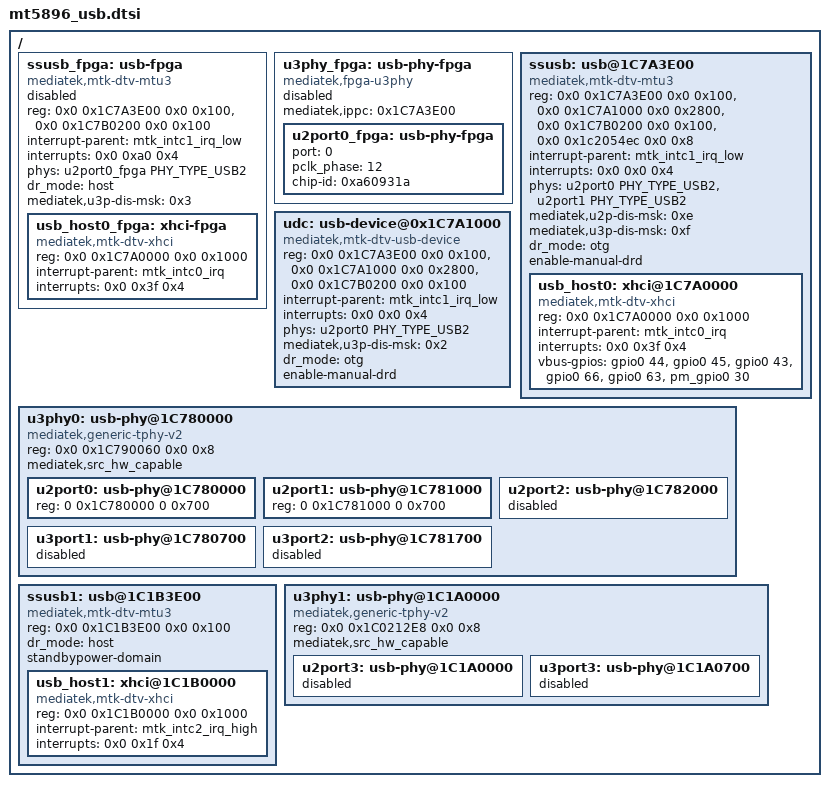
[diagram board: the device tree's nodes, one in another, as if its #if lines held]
// SPDX-License-Identifier: (GPL-2.0 OR BSD-3-Clause)
/*
 * Copyright (c) 2020 MediaTek Inc.
 */

/ {
	ssusb_fpga: usb-fpga {
		compatible = "mediatek,mtk-dtv-mtu3";
		reg = <0x0 0x1C7A3E00 0x0 0x100>,
			<0x0 0x1C7B0200 0x0 0x100>;
		reg-names = "ippc", "misc";
		interrupt-parent = <&mtk_intc1_irq_low>;
		interrupts = <0x0 0xa0 0x4>;
		phys = <&u2port0_fpga PHY_TYPE_USB2>;
		dr_mode = "host";
		#address-cells = <2>;
		#size-cells = <2>;
		ranges;
		mediatek,u3p-dis-msk = <0x3>;
		status = "disabled";

		usb_host0_fpga: xhci-fpga {
			compatible = "mediatek,mtk-dtv-xhci";
			reg = <0x0 0x1C7A0000 0x0 0x1000>;
			reg-names = "mac";
			interrupt-parent = <&mtk_intc0_irq>;
			interrupts = <0x0 0x3f 0x4>;
		};
	};

	u3phy_fpga: usb-phy-fpga {
		compatible = "mediatek,fpga-u3phy";
		mediatek,ippc = <0x1C7A3E00>;
		status = "disabled";

		u2port0_fpga: usb-phy-fpga {
			port = <0>;
			pclk_phase = <12>;
			chip-id = <0xa60931a>;
			#phy-cells = <1>;
		};
	};

	ssusb: usb@1C7A3E00 {
		compatible = "mediatek,mtk-dtv-mtu3";
		reg = <0x0 0x1C7A3E00 0x0 0x100>,
			<0x0 0x1C7A1000 0x0 0x2800>,
			<0x0 0x1C7B0200 0x0 0x100>,
			<0x0 0x1c2054ec 0x0 0x8>;
		reg-names = "ippc","mac","misc","dma_gt";
		interrupt-parent = <&mtk_intc1_irq_low>;
		interrupts = <0x0 0x0 0x4>;
		phys = <&u2port0 PHY_TYPE_USB2>,
			<&u2port1 PHY_TYPE_USB2>/*,
			<&u2port2 PHY_TYPE_USB2>,
			<&u3port1 PHY_TYPE_USB3>,
			<&u3port2 PHY_TYPE_USB3>*/;
#ifdef CONFIG_USB_XHCI_MTK_BOOT_PORT
		mediatek,u2p-dis-msk = <0xe>;
		mediatek,u3p-dis-msk = <0xf>;
#else
		mediatek,u3p-dis-msk = <0x2>;
#endif
		dr_mode = "otg";
		enable-manual-drd;
		#address-cells = <2>;
		#size-cells = <2>;
		ranges;
		status ="okay";

		usb_host0: xhci@1C7A0000 {
			compatible = "mediatek,mtk-dtv-xhci";
			reg = <0x0 0x1C7A0000 0x0 0x1000>;
			reg-names = "mac";
			interrupt-parent = <&mtk_intc0_irq>;
			interrupts = <0x0 0x3f 0x4>;
			vbus-gpios = <&gpio0 44 0>,
					<&gpio0 45 0>,
					<&gpio0 43 0>,
					<&gpio0 66 0>,
					<&gpio0 63 0>,
					<&pm_gpio0 30 0>;
			status ="okay";
		};
	};
	udc: usb-device@0x1C7A1000 {
		compatible = "mediatek,mtk-dtv-usb-device";
		reg = <0x0 0x1C7A3E00 0x0 0x100>,
			<0x0 0x1C7A1000 0x0 0x2800>,
			<0x0 0x1C7B0200 0x0 0x100>;
		reg-names = "ippc","mac","misc";
		interrupt-parent = <&mtk_intc1_irq_low>;
		interrupts = <0x0 0x0 0x4>;
		phys = <&u2port0 PHY_TYPE_USB2>;
		mediatek,u3p-dis-msk = <0x2>;
		dr_mode = "otg";
		enable-manual-drd;
		#address-cells = <2>;
		#size-cells = <2>;
		ranges;
		status ="okay";
		};
	u3phy0: usb-phy@1C780000 {
		compatible = "mediatek,generic-tphy-v2";
		reg = <0x0 0x1C790060 0x0 0x8>;
		reg-names = "i2c_ctrl_reg";
		#address-cells = <2>;
		#size-cells = <2>;
		mediatek,src_hw_capable;
		ranges;
		status = "okay";

		u2port0: usb-phy@1C780000 {
			reg = <0 0x1C780000 0 0x700>;
			#phy-cells = <1>;
			status = "okay";
		};

		u2port1: usb-phy@1C781000 {
			reg = <0 0x1C781000 0 0x700>;
			#phy-cells = <1>;
			status = "okay";
		};

		u2port2: usb-phy@1C782000 {
			status = "disabled";
		};

		u3port1: usb-phy@1C780700 {
			status = "disabled";
		};

		u3port2: usb-phy@1C781700 {
			status = "disabled";
		};
	};

	ssusb1: usb@1C1B3E00 {
		compatible = "mediatek,mtk-dtv-mtu3";
		reg = <0x0 0x1C1B3E00 0x0 0x100>;
		reg-names = "ippc";
		dr_mode = "host";
		#address-cells = <2>;
		#size-cells = <2>;
		ranges;
		standbypower-domain;
		status = "okay";

		usb_host1: xhci@1C1B0000 {
			compatible = "mediatek,mtk-dtv-xhci";
			reg = <0x0 0x1C1B0000 0x0 0x1000>;
			reg-names = "mac";
			interrupt-parent = <&mtk_intc2_irq_high>;
			interrupts = <0x0 0x1f 0x4>;
			status = "okay";
		};
	};

	u3phy1: usb-phy@1C1A0000 {
		compatible = "mediatek,generic-tphy-v2";
		reg = <0x0 0x1C0212E8 0x0 0x8>;
		reg-names = "i2c_ctrl_reg";
		#address-cells = <2>;
		#size-cells = <2>;
		mediatek,src_hw_capable;
		ranges;
		status = "okay";

		u2port3: usb-phy@1C1A0000 {
			status = "disabled";
		};

		u3port3: usb-phy@1C1A0700 {
			status = "disabled";
		};
	};
};
